AUTOSAR XML (schema 00049)
package /Components
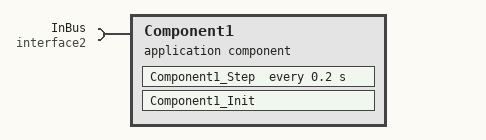
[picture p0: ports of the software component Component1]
  application sw component type Component1
    require port InBus: nonqueued-receiver-com-spec{data-element=b, init-value=Enum2_enum1}, required-interface=interface2
    behavior Component1_IB: data-type-mapping=myDataTypeMappingSet, handle-termination-and-restart=NO-SUPPORT
      timing event Event_Component1_Step: start-on-event=Component1_Step, period=0.2
      runnable Component1_Init
      runnable Component1_Step
